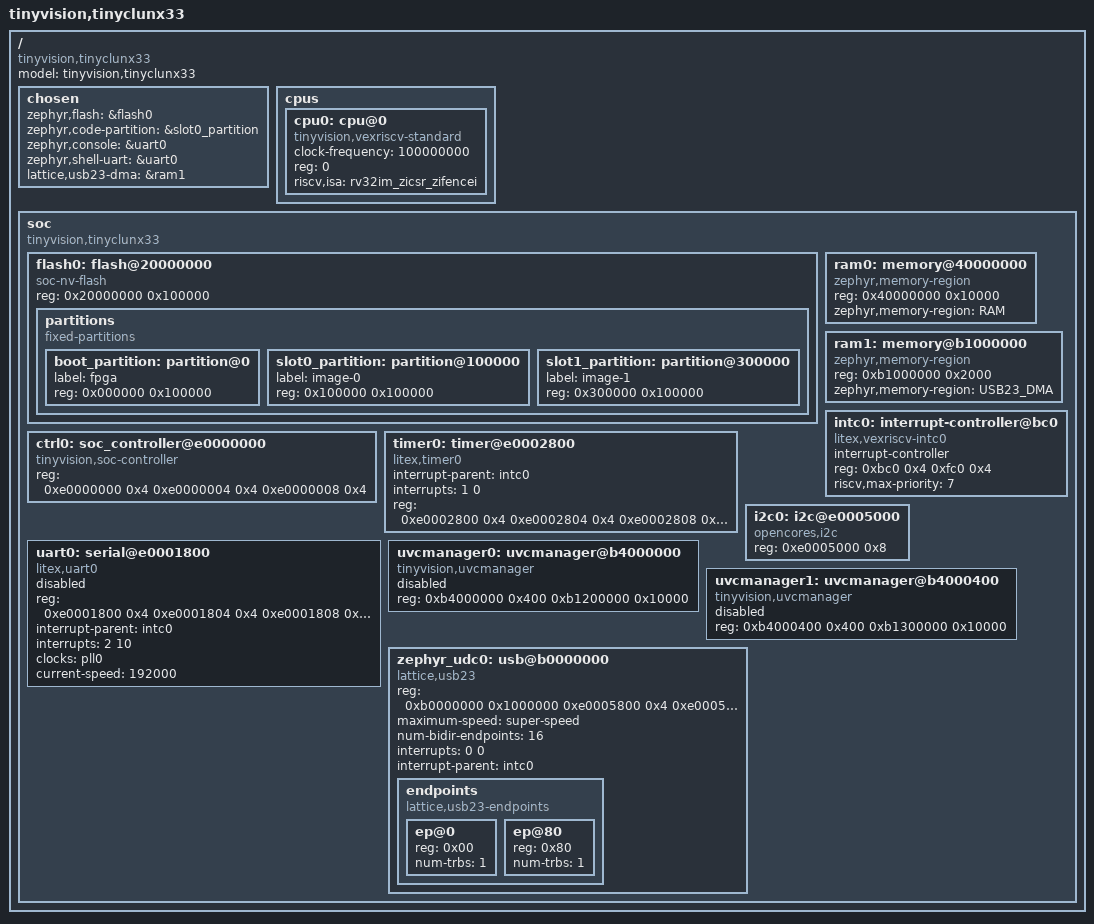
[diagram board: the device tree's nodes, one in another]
/*
 * Copyright (c) 2024 tinyVision.ai Inc.
 *
 * SPDX-License-Identifier: Apache-2.0
 */

/dts-v1/;
#include <riscv32-litex-vexriscv.dtsi>
#include <zephyr/dt-bindings/i2c/i2c.h>

/ {
	#address-cells = <1>;
	#size-cells = <1>;
	compatible = "tinyvision,tinyclunx33";
	model = "tinyvision,tinyclunx33";

	chosen {
		zephyr,flash = &flash0;
		zephyr,code-partition = &slot0_partition;
		zephyr,console = &uart0;
		zephyr,shell-uart = &uart0;
		lattice,usb23-dma = &ram1;
	};

	cpus {
		#address-cells = <1>;
		#size-cells = <0>;

		cpu0: cpu@0 {
			clock-frequency = <100000000>;
			compatible = "tinyvision,vexriscv-standard", "riscv";
			device_type = "cpu";
			reg = <0>;
			riscv,isa = "rv32im_zicsr_zifencei";
			status = "okay";
		};
	};

	soc {
		#address-cells = <1>;
		#size-cells = <1>;
		compatible = "tinyvision,tinyclunx33";
		ranges;

		flash0: flash@20000000 {
			compatible = "soc-nv-flash";

			reg = <0x20000000 0x100000>;

			partitions {
				compatible = "fixed-partitions";
				#address-cells = <1>;
				#size-cells = <1>;

				boot_partition: partition@0 {
					label = "fpga";
					reg = <0x000000 0x100000>;
				};

				slot0_partition: partition@100000 {
					label = "image-0";
					reg = <0x100000 0x100000>;
				};

				slot1_partition: partition@300000 {
					label = "image-1";
					reg = <0x300000 0x100000>;
				};
			};
		};

		ram0: memory@40000000 {
			compatible = "zephyr,memory-region";
			device_type = "memory";
			reg = <0x40000000 0x10000>;
			zephyr,memory-region = "RAM";
		};

		ram1: memory@b1000000 {
			compatible = "zephyr,memory-region";
			device_type = "memory";
			reg = <0xb1000000 0x2000>;
			zephyr,memory-region = "USB23_DMA";
		};

		ctrl0: soc_controller@e0000000 {
			compatible = "tinyvision,soc-controller";
			reg = <0xe0000000 0x4
				0xe0000004 0x4
				0xe0000008 0x4>;
			reg-names = "reset",
				"scratch",
				"bus_errors";
		};

		intc0: interrupt-controller@bc0 {
			compatible = "litex,vexriscv-intc0";
			#address-cells = <0>;
			#interrupt-cells = <2>;
			interrupt-controller;
			reg = <0xbc0 0x4 0xfc0 0x4>;
			reg-names = "irq_mask", "irq_pending";
			riscv,max-priority = <7>;
		};

		timer0: timer@e0002800 {
			compatible = "litex,timer0";
			interrupt-parent = <&intc0>;
			interrupts = <1 0>;
			reg = <0xe0002800 0x4
				0xe0002804 0x4
				0xe0002808 0x4
				0xe000280c 0x4
				0xe0002810 0x4
				0xe0002814 0x4
				0xe0002818 0x4
				0xe000281c 0x4
				0xe0002820 0x4
				0xe0002824 0x8>;
			reg-names =
				"load",
				"reload",
				"en",
				"update_value",
				"value",
				"ev_status",
				"ev_pending",
				"ev_enable",
				"uptime_latch",
				"uptime_cycles";
		};

		uart0: serial@e0001800 {
			compatible = "litex,uart0";
			reg = <0xe0001800 0x4
				0xe0001804 0x4
				0xe0001808 0x4
				0xe000180c 0x4
				0xe0001810 0x4
				0xe0001814 0x4
				0xe0001818 0x4
				0xe000181c 0x4>;
			reg-names = "rxtx",
				"txfull",
				"rxempty",
				"ev_status",
				"ev_pending",
				"ev_enable",
				"txempty",
				"rxfull";
			interrupt-parent = <&intc0>;
			interrupts = <2 10>;

			/* Turned off to let the board start when ther is no PLL */
			clocks = <&pll0>;

			/* Value for RTL Reference Design v0.5 */
			current-speed = <192000>;

			status = "disabled";
		};

		i2c0: i2c@e0005000 {
			compatible = "opencores,i2c";
			reg = <0xe0005000 0x8>;
			reg-names = "control";
			status = "okay";
		};

		uvcmanager0: uvcmanager@b4000000 {
			compatible = "tinyvision,uvcmanager";
			status = "disabled";
			reg = <	0xb4000000 0x400
				0xb1200000 0x10000>;
			reg-names =
				"base",
				"fifo";
		};

		uvcmanager1: uvcmanager@b4000400 {
			compatible = "tinyvision,uvcmanager";
			status = "disabled";
			reg = <	0xb4000400 0x400
				0xb1300000 0x10000>;
			reg-names =
				"base",
				"fifo";
		};

		zephyr_udc0: usb@b0000000 {
			compatible = "lattice,usb23";
			reg = <	0xb0000000 0x1000000
				0xe0005800 0x4
				0xe0005804 0x4
				0xe0005808 0x4>;
			reg-names =
				"base",
				"ev_status",
				"ev_pending",
				"ev_enable";
			maximum-speed = "super-speed";
			num-bidir-endpoints = <16>;
			interrupts = <0 0>;
			interrupt-names = "usb";
			interrupt-parent = <&intc0>;
			status = "okay";

			endpoints {
				compatible = "lattice,usb23-endpoints";
				#address-cells = <1>;
				#size-cells = <0>;

				ep@0 {
					reg = <0x00>;
					num-trbs = <1>;
				};

				ep@80 {
					reg = <0x80>;
					num-trbs = <1>;
				};

				/* Only define a small number of endpoints to
				 * save memory. The application can choose
				 * exacly how many endpoints and TRB they wish
				 * to use.
				 */
			};
		};
	};
};
